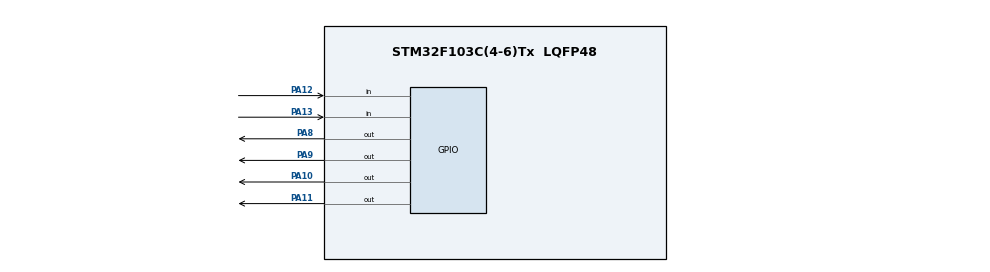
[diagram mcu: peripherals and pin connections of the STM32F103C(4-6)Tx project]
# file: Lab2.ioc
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Mcu.Family=STM32F1
Mcu.Name=STM32F103C(4-6)Tx
Mcu.Package=LQFP48
NVIC.PriorityGroup=NVIC_PRIORITYGROUP_4
PA10.Signal=GPIO_Output
PA11.Signal=GPIO_Output
PA12.Signal=GPIO_Input
PA13.Signal=GPIO_Input
PA8.Signal=GPIO_Output
PA9.Signal=GPIO_Output
ProjectManager.HeapSize=0x200
ProjectManager.StackSize=0x400
ProjectManager.TargetToolchain=STM32CubeIDE
RCC.APB1Freq_Value=8000000
RCC.APB2Freq_Value=8000000
board=custom

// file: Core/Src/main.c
/* USER CODE BEGIN Header */
/**
  ******************************************************************************
  * @file           : main.c
  * @brief          : Main program body
  ******************************************************************************
  * @attention
  *
  * Copyright (c) 2023 STMicroelectronics.
  * All rights reserved.
  *
  * This software is licensed under terms that can be found in the LICENSE file
  * in the root directory of this software component.
  * If no LICENSE file comes with this software, it is provided AS-IS.
  *
  ******************************************************************************
  */
/* USER CODE END Header */
#include "main.h"
#include "gpio.h"
#include "string.h"
#include "stdlib.h"

void SystemClock_Config(void);

int main(void)
{

  /* MCU Configuration--------------------------------------------------------*/

  /* Reset of all peripherals, Initializes the Flash interface and the Systick. */
  HAL_Init();

  /* Configure the system clock */
  SystemClock_Config();

  /* Initialize all configured peripherals */
  MX_GPIO_Init();

  /* Infinite loop */
  /* USER CODE BEGIN WHILE */
  int Press = 0;
   int T1 = 0;
   int T2 = 1;
   int stack = 0;
   int LEDS[4];
   int Start = 0;
   int i = 0;
     /* Infinite loop */
     /* USER CODE BEGIN WHILE */
     while (1)
     {
       /* USER CODE END WHILE */
   	  if(HAL_GPIO_ReadPin(GPIOA, GPIO_PIN_13) == 0 && HAL_GPIO_ReadPin(GPIOA, GPIO_PIN_12) == 0)
   	  	  {
   		  Press = 0;
   	  	  }
   	  if(HAL_GPIO_ReadPin(GPIOA, GPIO_PIN_13) == 1 && Press == 0)
   	  {
   		  T1 = T1 + 1;
   		  T1 = T1 % 4;
   		  Press = 1;
   	  }
   	  if(HAL_GPIO_ReadPin(GPIOA, GPIO_PIN_12) == 1 && Press == 0)
   	  {
   		  T2 = T2 + 1;
   		  T2 = T2 % 5;
   		  Press = 1;
   	  }
   	  stack = T2;
   	  memset(LEDS,0,sizeof(int)*4);

i = 0;
Start = 0;
   while(stack > 0)
   {
	   if(i==T1)
	   {Start=1;}
 	  if(Start == 1)
 	  {LEDS[i]=1;
 	  stack = stack - 1;}
 	  i = i + 1;
 	  i = i % 4;
   }

	 if(LEDS[3] == 1){HAL_GPIO_WritePin(GPIOA, GPIO_PIN_11, 1);}
	 if(LEDS[2] == 1){HAL_GPIO_WritePin(GPIOA, GPIO_PIN_10, 1);}
	 if(LEDS[1] == 1){HAL_GPIO_WritePin(GPIOA, GPIO_PIN_9, 1);}
	 if(LEDS[0] == 1){HAL_GPIO_WritePin(GPIOA, GPIO_PIN_8, 1);}
	 if(LEDS[3] == 0){HAL_GPIO_WritePin(GPIOA, GPIO_PIN_11, 0);}
	 if(LEDS[2] == 0){HAL_GPIO_WritePin(GPIOA, GPIO_PIN_10, 0);}
	 if(LEDS[1] == 0){HAL_GPIO_WritePin(GPIOA, GPIO_PIN_9, 0);}
	 if(LEDS[0] == 0){HAL_GPIO_WritePin(GPIOA, GPIO_PIN_8, 0);}

 }
  /* USER CODE END 3 */
}

void SystemClock_Config(void)
{
  RCC_OscInitTypeDef RCC_OscInitStruct = {0};
  RCC_ClkInitTypeDef RCC_ClkInitStruct = {0};

  /** Initializes the RCC Oscillators according to the specified parameters
  * in the RCC_OscInitTypeDef structure.
  */
  RCC_OscInitStruct.OscillatorType = RCC_OSCILLATORTYPE_HSI;
  RCC_OscInitStruct.HSIState = RCC_HSI_ON;
  RCC_OscInitStruct.HSICalibrationValue = RCC_HSICALIBRATION_DEFAULT;
  RCC_OscInitStruct.PLL.PLLState = RCC_PLL_NONE;
  if (HAL_RCC_OscConfig(&RCC_OscInitStruct) != HAL_OK)
  {
    Error_Handler();
  }

  /** Initializes the CPU, AHB and APB buses clocks
  */
  RCC_ClkInitStruct.ClockType = RCC_CLOCKTYPE_HCLK|RCC_CLOCKTYPE_SYSCLK
                              |RCC_CLOCKTYPE_PCLK1|RCC_CLOCKTYPE_PCLK2;
  RCC_ClkInitStruct.SYSCLKSource = RCC_SYSCLKSOURCE_HSI;
  RCC_ClkInitStruct.AHBCLKDivider = RCC_SYSCLK_DIV1;
  RCC_ClkInitStruct.APB1CLKDivider = RCC_HCLK_DIV1;
  RCC_ClkInitStruct.APB2CLKDivider = RCC_HCLK_DIV1;

  if (HAL_RCC_ClockConfig(&RCC_ClkInitStruct, FLASH_LATENCY_0) != HAL_OK)
  {
    Error_Handler();
  }
}

void Error_Handler(void)
{
  __disable_irq();
  while (1)
  {
  }
}
